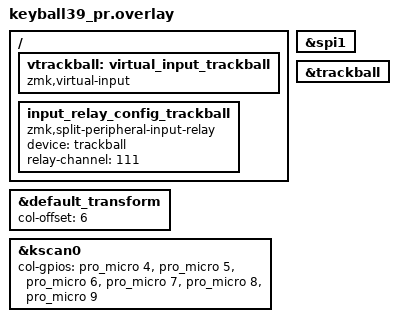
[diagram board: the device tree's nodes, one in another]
/*
 * SPDX-License-Identifier: MIT
 * Dongle build: RIGHT half is a peripheral that owns the trackball and
 * relays its motion to the dongle (central) over split channel 111.
 */

#include "keyball39.dtsi"
#include "keyball39_pmw3610.dtsi"

&default_transform {
    col-offset = <6>;
};

&kscan0 {
    col-gpios
        = <&pro_micro 4 GPIO_ACTIVE_HIGH>
        , <&pro_micro 5 GPIO_ACTIVE_HIGH>
        , <&pro_micro 6 GPIO_ACTIVE_HIGH>
        , <&pro_micro 7 GPIO_ACTIVE_HIGH>
        , <&pro_micro 8 GPIO_ACTIVE_HIGH>
        , <&pro_micro 9 GPIO_ACTIVE_HIGH>
        ;
};

&spi1 {
    status = "okay";
};

&trackball {
    status = "okay";
};

/ {
    vtrackball: virtual_input_trackball {
        compatible = "zmk,virtual-input";
    };

    /* send raw trackball motion to the dongle (central) over channel 111 */
    input_relay_config_trackball {
        compatible = "zmk,split-peripheral-input-relay";
        device = <&trackball>;
        relay-channel = <111>;
    };
};
